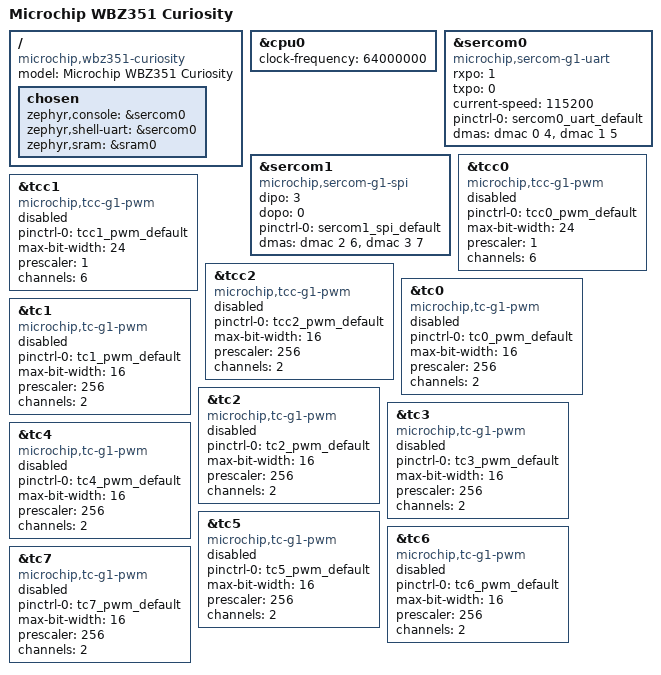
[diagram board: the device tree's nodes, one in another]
/*
 * Copyright (c) 2025 Microchip Technology Inc.
 *
 * SPDX-License-Identifier: Apache-2.0
 */

/dts-v1/;
#include <microchip/pic32c/pic32cx_bz/bz3x/bz3/pic32cx5109bz31048.dtsi>
#include "wbz351_curiosity-pinctrl.dtsi"
#include <zephyr/dt-bindings/input/input-event-codes.h>
#include <zephyr/dt-bindings/i2c/i2c.h>

/ {
	model = "Microchip WBZ351 Curiosity";
	compatible = "microchip,wbz351-curiosity";

	chosen {
		zephyr,console = &sercom0;
		zephyr,shell-uart = &sercom0;
		zephyr,sram = &sram0;
	};
};

&cpu0 {
	clock-frequency = <64000000>;
};


&sercom0 {
	status = "okay";
	compatible = "microchip,sercom-g1-uart";
	rxpo = <1>;
	txpo = <0>;
	current-speed = <115200>;
	pinctrl-0 = <&sercom0_uart_default>;
	pinctrl-names = "default";

	dmas = <&dmac 0 4>, <&dmac 1 5>;
	dma-names = "rx", "tx";
};

/* sercom 1 in spi mode, so disable uart mode
 *&sercom1 {
 *	status = "okay";
 *	compatible = "microchip,sercom-g1-uart";
 *	rxpo = <1>;
 *	txpo = <0>;
 *	current-speed = <115200>;
 *	pinctrl-0 = <&sercom1_uart_default>;
 *	pinctrl-names = "default";
 *
 *	dmas = <&dmac 2 6>, <&dmac 3 7>;
 *	dma-names = "rx", "tx";
 *};
 */

/* sercom 1 spi master mode */
&sercom1 {
	status = "okay";
	compatible = "microchip,sercom-g1-spi";
	dipo = <3>;
	dopo = <0>;
	#address-cells = <1>;
	#size-cells = <0>;
	pinctrl-0 = <&sercom1_spi_default>;
	pinctrl-names = "default";

	dmas = <&dmac 2 6>, <&dmac 3 7>;
	dma-names = "rx", "tx";
};

/* sercom 1 spi slave mode
 *&sercom1 {
 *	status = "okay";
 *	compatible = "microchip,sercom-g1-spi";
 *	dipo = <0>;
 *	dopo = <2>;
 *	#address-cells = <1>;
 *	#size-cells = <0>;
 *	pinctrl-0 = <&sercom1_spi_default>;
 *	pinctrl-names = "default";
 *
 *	dmas = <&dmac 2 6>, <&dmac 3 7>;
 *	dma-names = "rx", "tx";
 *};
 */

&tcc0 {
	status = "disabled";
	compatible = "microchip,tcc-g1-pwm";
	#pwm-cells = <3>;
	pinctrl-0 = <&tcc0_pwm_default>;
	pinctrl-names = "default";
	max-bit-width = <24>;
	prescaler = <1>;
	channels = <6>;
};

&tcc1 {
	status = "disabled";
	compatible = "microchip,tcc-g1-pwm";
	#pwm-cells = <3>;
	pinctrl-0 = <&tcc1_pwm_default>;
	pinctrl-names = "default";
	max-bit-width = <24>;
	prescaler = <1>;
	channels = <6>;
};

&tcc2 {
	status = "disabled";
	compatible = "microchip,tcc-g1-pwm";
	#pwm-cells = <3>;
	pinctrl-0 = <&tcc2_pwm_default>;
	pinctrl-names = "default";
	max-bit-width = <16>;
	prescaler = <256>;
	channels = <2>;
};

/* TCC: In 16-bit/32-bit mode, the pulse value is written to CC[1]. This is because they are in MPWM
 *		mode. In MPWM mode, the wave output will can be observed in WO[1]
 */
&tc0 {
	status = "disabled";
	compatible = "microchip,tc-g1-pwm";
	#pwm-cells = <3>;
	pinctrl-0 = <&tc0_pwm_default>;
	pinctrl-names = "default";
	max-bit-width = <16>;
	prescaler = <256>;
	channels = <2>;
};

&tc1 {
	status = "disabled";
	compatible = "microchip,tc-g1-pwm";
	#pwm-cells = <3>;
	pinctrl-0 = <&tc1_pwm_default>;
	pinctrl-names = "default";
	max-bit-width = <16>;
	prescaler = <256>;
	channels = <2>;
};

&tc2 {
	status = "disabled";
	compatible = "microchip,tc-g1-pwm";
	#pwm-cells = <3>;
	pinctrl-0 = <&tc2_pwm_default>;
	pinctrl-names = "default";
	max-bit-width = <16>;
	prescaler = <256>;
	channels = <2>;
};

&tc3 {
	status = "disabled";
	compatible = "microchip,tc-g1-pwm";
	#pwm-cells = <3>;
	pinctrl-0 = <&tc3_pwm_default>;
	pinctrl-names = "default";
	max-bit-width = <16>;
	prescaler = <256>;
	channels = <2>;
};

&tc4 {
	status = "disabled";
	compatible = "microchip,tc-g1-pwm";
	#pwm-cells = <3>;
	pinctrl-0 = <&tc4_pwm_default>;
	pinctrl-names = "default";
	max-bit-width = <16>;
	prescaler = <256>;
	channels = <2>;
};

&tc5 {
	status = "disabled";
	compatible = "microchip,tc-g1-pwm";
	#pwm-cells = <3>;
	pinctrl-0 = <&tc5_pwm_default>;
	pinctrl-names = "default";
	max-bit-width = <16>;
	prescaler = <256>;
	channels = <2>;
};

&tc6 {
	status = "disabled";
	compatible = "microchip,tc-g1-pwm";
	#pwm-cells = <3>;
	pinctrl-0 = <&tc6_pwm_default>;
	pinctrl-names = "default";
	max-bit-width = <16>;
	prescaler = <256>;
	channels = <2>;
};

&tc7 {
	status = "disabled";
	compatible = "microchip,tc-g1-pwm";
	#pwm-cells = <3>;
	pinctrl-0 = <&tc7_pwm_default>;
	pinctrl-names = "default";
	max-bit-width = <16>;
	prescaler = <256>;
	channels = <2>;
};
